# UPD70F3508 register map
Vendor: Renesas; Series: V850E2/Px4; File version: 1.0
CPU: other r0p0, little endian, no MPU, FPU, 4 interrupt priority bits
Registers are 8-bit, read-write, reset 0x0 unless marked. A register's access mark holds for its fields unless they carry their own. Offsets are from the block's base; [hi:lo] are bit positions.

## CSIG1_B1 — Clocked Serial Interface G 1 - base1 region (CTL0, STR0, STCR0, BCTL0, TX0W, TX0H, RX0)
Base 0xFFFFE500
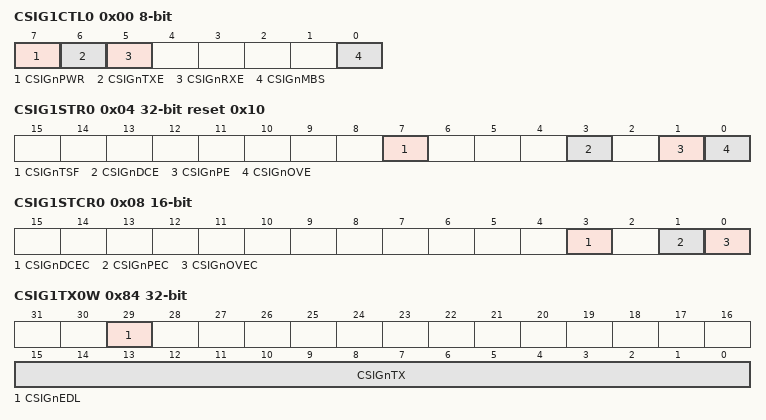
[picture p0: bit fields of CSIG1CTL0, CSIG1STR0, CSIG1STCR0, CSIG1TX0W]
0x00 CSIG1CTL0 — CSIG1 Control Register 0 - operation clock, TX/RX enable
  [7] CSIGnPWR — Operation clock: 0=stop, 1=provide
  [6] CSIGnTXE — Transmission enable: 0=disabled, 1=enabled
  [5] CSIGnRXE — Reception enable: 0=disabled, 1=enabled
  [0] CSIGnMBS — Must be set to 1 before activating CSIG
0x04 CSIG1STR0 32-bit ro reset 0x10 — CSIG1 Status Register 0
  [7] CSIGnTSF — Transfer status: 0=idle, 1=transfer in progress or pending
  [3] CSIGnDCE — Data consistency error flag: 0=none, 1=error detected
  [1] CSIGnPE — Parity error flag: 0=none, 1=parity error detected
  [0] CSIGnOVE — Overrun error flag: 0=none, 1=overrun detected
0x08 CSIG1STCR0 16-bit — CSIG1 Status Clear Register 0 - clears STR0 error flags
  [3] CSIGnDCEC — Clear DCE flag: write 1 to clear CSIGnSTR0.CSIGnDCE
  [1] CSIGnPEC — Clear PE flag: write 1 to clear CSIGnSTR0.CSIGnPE
  [0] CSIGnOVEC — Clear OVE flag: write 1 to clear CSIGnSTR0.CSIGnOVE
0x80 CSIG1BCTL0 reset 0x1 — CSIG1 Receive-Only Mode Control Register 0
  [0] CSIGnSCE — Next reception enable on RX0 read: 0=disabled, 1=enabled
0x84 CSIG1TX0W 32-bit — CSIG1 Transmission Register 0 - word access (use with EDL)
  [29] CSIGnEDL — Extended data length: 0=normal, 1=transmit as 16-bit EDL block
  [15:0] CSIGnTX — Transmit data [15:0]
0x88 CSIG1TX0H 16-bit — CSIG1 Transmission Register 0 - half-word access (use without EDL)
  [15:0] CSIGnTX — Transmit data [15:0]
0x8C CSIG1RX0 16-bit ro — CSIG1 Reception Register 0
  [15:0] CSIGnRX — Received data [15:0]

## CSIG2_B1 — Clocked Serial Interface G 2 - base1 region (CTL0, STR0, STCR0, BCTL0, TX0W, TX0H, RX0)
Base 0xFFFFE600
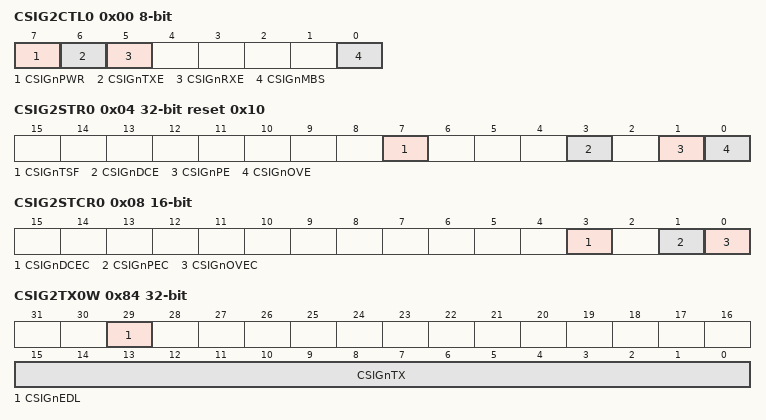
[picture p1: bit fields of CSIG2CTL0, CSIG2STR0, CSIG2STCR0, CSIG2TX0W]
0x00 CSIG2CTL0 — CSIG2 Control Register 0 - operation clock, TX/RX enable
  [7] CSIGnPWR — Operation clock: 0=stop, 1=provide
  [6] CSIGnTXE — Transmission enable: 0=disabled, 1=enabled
  [5] CSIGnRXE — Reception enable: 0=disabled, 1=enabled
  [0] CSIGnMBS — Must be set to 1 before activating CSIG
0x04 CSIG2STR0 32-bit ro reset 0x10 — CSIG2 Status Register 0
  [7] CSIGnTSF — Transfer status: 0=idle, 1=transfer in progress or pending
  [3] CSIGnDCE — Data consistency error flag: 0=none, 1=error detected
  [1] CSIGnPE — Parity error flag: 0=none, 1=parity error detected
  [0] CSIGnOVE — Overrun error flag: 0=none, 1=overrun detected
0x08 CSIG2STCR0 16-bit — CSIG2 Status Clear Register 0 - clears STR0 error flags
  [3] CSIGnDCEC — Clear DCE flag: write 1 to clear CSIGnSTR0.CSIGnDCE
  [1] CSIGnPEC — Clear PE flag: write 1 to clear CSIGnSTR0.CSIGnPE
  [0] CSIGnOVEC — Clear OVE flag: write 1 to clear CSIGnSTR0.CSIGnOVE
0x80 CSIG2BCTL0 reset 0x1 — CSIG2 Receive-Only Mode Control Register 0
  [0] CSIGnSCE — Next reception enable on RX0 read: 0=disabled, 1=enabled
0x84 CSIG2TX0W 32-bit — CSIG2 Transmission Register 0 - word access (use with EDL)
  [29] CSIGnEDL — Extended data length: 0=normal, 1=transmit as 16-bit EDL block
  [15:0] CSIGnTX — Transmit data [15:0]
0x88 CSIG2TX0H 16-bit — CSIG2 Transmission Register 0 - half-word access (use without EDL)
  [15:0] CSIGnTX — Transmit data [15:0]
0x8C CSIG2RX0 16-bit ro — CSIG2 Reception Register 0
  [15:0] CSIGnRX — Received data [15:0]

## DCRA0 — Data CRC Function A, instance 0 — CIN/COUT registers (base0 = 0xFFFFFA00)
Base 0xFFFFFA00
0x00 DCRA0CIN 32-bit — CRC Input Register — instance 0
  [31:0] DCRA0CIN — Input data for CRC calculation (valid width controlled by DCRA0CTL.DCRA0ISZ)
0x04 DCRA0COUT 32-bit reset 0xFFFFFFFF — CRC Data Register — instance 0; stores CRC result; read returns value XOR'd with poly constant
  [31:0] DCRA0COUT — CRC result; initialize with starting value before first write to DCRA0CIN

## DCRA1 — Data CRC Function A, instance 1 — CIN/COUT registers (base0 = 0xFFFFFB00)
Base 0xFFFFFB00
0x00 DCRA1CIN 32-bit — CRC Input Register — instance 1
  [31:0] DCRA1CIN — Input data for CRC calculation (valid width controlled by DCRA1CTL.DCRA1ISZ)
0x04 DCRA1COUT 32-bit reset 0xFFFFFFFF — CRC Data Register — instance 1; stores CRC result; read returns value XOR'd with poly constant
  [31:0] DCRA1COUT — CRC result; initialize with starting value before first write to DCRA1CIN

## POFLVI — Power-On Flag and LVI Status registers (base cluster 0xFFFFFC00)
Base 0xFFFFFC00
0x00 POF ro reset 0x1 — Power-on Flag Register — bit 0 set when EVDD falls below POF detection voltage; read-only 8-bit
  [0] POF — Power-on flag: 0=EVDD above detection voltage, 1=EVDD below detection voltage
0x04 POFC wo — Power-on Flag Clear Register — write 1 to bit 0 to clear POF.POF; reads as 00H
  [0] POFC — POF clear: writing 1 clears POF.POF to 0
0x08 POFS wo — Power-on Flag Set Register — write 1 to bit 0 to set POF.POF (test use); reads as 00H
  [0] POFS — POF set: writing 1 sets POF.POF to 1
0x10 LVISF ro — LVI Status Flag Register — bit 0 indicates current LVI detection state; read-only 8-bit
  [0] LVISF — LVI detection flag: 0=EVDD not low (or LVI not operating), 1=EVDD low

## UARTH_IC0 — LIN Communications Slave Operation Baud-Rate Detection Registers (IC0REG0/IC0REG1)
Base 0xFFFFFE00
0x00 IC0REG0 32-bit — LIN Baud-Rate Detection Register 0 — TAUA0 channel input selection
0x04 IC0REG1 32-bit — LIN Baud-Rate Detection Register 1 — TAUA1 channel input selection
